# MCU_NAVSS0_SEC_PROXY0_CFG_RT register map
Vendor: Texas Instruments
Peripheral module from a debugger description file (folder J7ES).
Registers are 32-bit, access per field, reset 0x0 unless marked. A register's access mark holds for its fields unless they carry their own. Offsets are as the file gives them; lines under a group give offsets from that group; [hi:lo] are bit positions; {n}, {i} and the like mark numbered series; 'fields as' and 'values as' point back to an identical list; <NAME> marks a mode.

## MCU_NAVSS0_SEC_PROXY0_CFG_RT
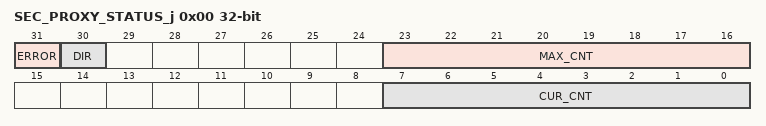
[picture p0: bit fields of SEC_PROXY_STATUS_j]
0x00 SEC_PROXY_STATUS_j — The Status Register gives status for proxy thread j. Offset =0h + (j * 1000h); where j = 0h to 9Fh for NAVSS0_SEC_PROXY0_CFG_RT j = 0h to 59h for MCU_NAVSS0_SEC_PROXY0_CFG_RT
  [31] ERROR rw — Error detected on proxy thread. The error will also use the err_evt field to generate an error event which can generate an interrupt. While in error a proxy thread will not process any operations. Write a 0 to clear the error and reset the proxy thread.
  [30] DIR ro — Direction for the proxy thread.
  [23:16] MAX_CNT ro — Max message count allowed for an outbound proxy thread.
  [7:0] CUR_CNT ro — Current message count for the proxy thread. For an inbound proxy this is the number of available messages. For an outbound proxy this is the number of free messages that can be written.
0x04 SEC_PROXY_THR_j rw — The Threshold Register controls the threshold for proxy thread j events. Offset =4h + (j * 1000h); where j = 0h to 9Fh for NAVSS0_SEC_PROXY0_CFG_RT j = 0h to 59h for MCU_NAVSS0_SEC_PROXY0_CFG_RT
  [7:0] THR_CNT — Threshold count that causes proxy thread events. For an outbound proxy this will be the number of free messages to cause an event. For an inbound proxy this will be the number of available messages to cause an event.
